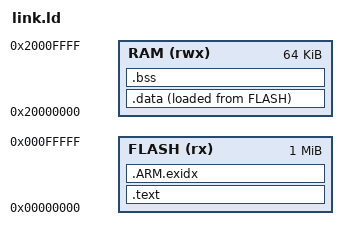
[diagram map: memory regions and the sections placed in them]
/* Cortex-M3, QEMU machine mps2-an385. RAM is deliberately limited to 64 KiB. */
MEMORY
{
  FLASH (rx)  : ORIGIN = 0x00000000, LENGTH = 1024K
  RAM   (rwx) : ORIGIN = 0x20000000, LENGTH = 64K
}
ENTRY(reset_handler)
SECTIONS
{
  .text : { KEEP(*(.vectors)) *(.text*) *(.rodata*) . = ALIGN(4); } > FLASH
  .ARM.exidx : { *(.ARM.exidx*) } > FLASH
  _sidata = LOADADDR(.data);
  .data : { _sdata = .; *(.data*) . = ALIGN(4); _edata = .; } > RAM AT > FLASH
  .bss  : { _sbss = .; *(.bss*) *(COMMON) . = ALIGN(4); _ebss = .; } > RAM
  end = .; _end = .;
  _stack_bottom = .;
  _stack_top = ORIGIN(RAM) + LENGTH(RAM);
}
